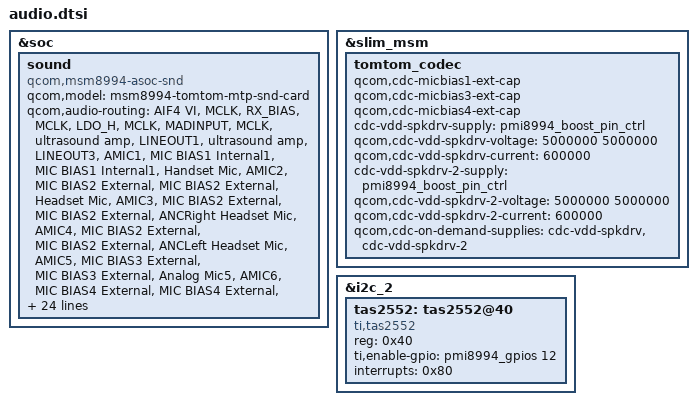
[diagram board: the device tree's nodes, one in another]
&soc {
    sound {
        compatible = "qcom,msm8994-asoc-snd";
        qcom,model = "msm8994-tomtom-mtp-snd-card";

        qcom,audio-routing =
            "AIF4 VI", "MCLK",
            "RX_BIAS", "MCLK",
            "LDO_H", "MCLK",
            "MADINPUT", "MCLK",
            "ultrasound amp", "LINEOUT1",
            "ultrasound amp", "LINEOUT3",
            "AMIC1", "MIC BIAS1 Internal1",
            "MIC BIAS1 Internal1", "Handset Mic",
            "AMIC2", "MIC BIAS2 External",
            "MIC BIAS2 External", "Headset Mic",
            "AMIC3", "MIC BIAS2 External",
            "MIC BIAS2 External", "ANCRight Headset Mic",
            "AMIC4", "MIC BIAS2 External",
            "MIC BIAS2 External", "ANCLeft Headset Mic",
            "AMIC5", "MIC BIAS3 External",
            "MIC BIAS3 External", "Analog Mic5",
            "AMIC6", "MIC BIAS4 External",
            "MIC BIAS4 External", "Analog Mic6",
            "DMIC1", "MIC BIAS1 External",
            "MIC BIAS1 External", "Digital Mic1",
            "DMIC2", "MIC BIAS1 External",
            "MIC BIAS1 External", "Digital Mic2",
            "DMIC3", "MIC BIAS3 External",
            "MIC BIAS3 External", "Digital Mic3",
            "DMIC4", "MIC BIAS3 External",
            "MIC BIAS3 External", "Digital Mic4",
            "DMIC5", "MIC BIAS4 External",
            "MIC BIAS4 External", "Digital Mic5",
            "DMIC6", "MIC BIAS4 External",
            "MIC BIAS4 External", "Digital Mic6";

        qcom,cdc-micbias2-headset-only;
        qcom,mbhc-audio-jack-type = "4-pole-jack";
        asoc-codec = <&tas2552>;
        asoc-codec-names = "ti,tas2552";

		asoc-platform = <&pcm0>, <&pcm1>, <&pcm2>, <&pcm3>, <&voip>, <&voice>,
				<&loopback>, <&compress>, <&hostless>,
				<&afe>, <&lsm>, <&routing>, <&cpe>, <&compr>;
		asoc-platform-names = "msm-pcm-dsp.0", "msm-pcm-dsp.1", "msm-pcm-dsp.2", "msm-pcm-dsp.3",
				"msm-voip-dsp", "msm-pcm-voice", "msm-pcm-loopback",
				"msm-compress-dsp", "msm-pcm-hostless", "msm-pcm-afe",
				"msm-lsm-client", "msm-pcm-routing", "msm-cpe-lsm",
				"msm-compr-dsp";
    };
};

&slim_msm {
    tomtom_codec {
        qcom,cdc-micbias1-ext-cap;
        qcom,cdc-micbias3-ext-cap;
        qcom,cdc-micbias4-ext-cap;
        cdc-vdd-spkdrv-supply = <&pmi8994_boost_pin_ctrl>;
        qcom,cdc-vdd-spkdrv-voltage = <5000000 5000000>;
        qcom,cdc-vdd-spkdrv-current = <600000>;

        cdc-vdd-spkdrv-2-supply = <&pmi8994_boost_pin_ctrl>;
        qcom,cdc-vdd-spkdrv-2-voltage = <5000000 5000000>;
        qcom,cdc-vdd-spkdrv-2-current = <600000>;

        qcom,cdc-on-demand-supplies = "cdc-vdd-spkdrv",
                                      "cdc-vdd-spkdrv-2";
    };
};

&i2c_2 {
    status = "okay";
    tas2552: tas2552@40 {  
        reg = <0x40>;  
        compatible = "ti,tas2552";
        ti,enable-gpio = <&pmi8994_gpios 12 0x00>;  
        interrupts = <0x80>;
    };
};
